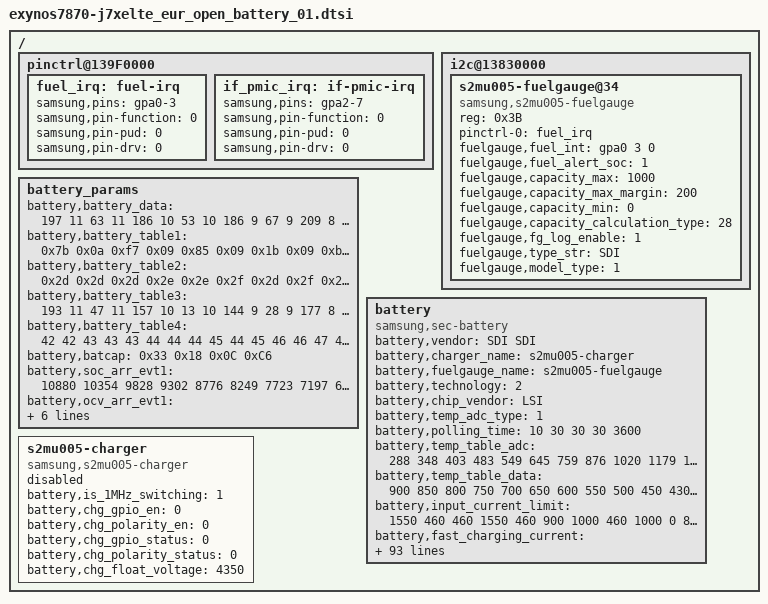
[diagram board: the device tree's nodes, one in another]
/*
 * SAMSUNG UNIVERSAL5433 board device tree source
 *
 * Copyright (c) 2013 Samsung Electronics Co., Ltd.
 *		http://www.samsung.com
 *
 * This program is free software; you can redistribute it and/or modify
 * it under the terms of the GNU General Public License version 2 as
 * published by the Free Software Foundation.
*/

/ {
	pinctrl@139F0000 {
		fuel_irq: fuel-irq {
			samsung,pins = "gpa0-3";
			samsung,pin-function = <0>;
			samsung,pin-pud = <0>;
			samsung,pin-drv = <0>;
		};
	};

	pinctrl@139F0000 {
		if_pmic_irq: if-pmic-irq {
			samsung,pins = "gpa2-7";
			samsung,pin-function = <0>;
			samsung,pin-pud = <0>;
			samsung,pin-drv = <0>;
		};
	};

	i2c@13830000 {
		status = "okay";
		s2mu005-fuelgauge@34 {
			compatible = "samsung,s2mu005-fuelgauge";
			reg = <0x3B>;
			pinctrl-names = "default";
			pinctrl-0 = <&fuel_irq>;
			fuelgauge,fuel_int = <&gpa0 3 0>;
			fuelgauge,fuel_alert_soc = <1>;
			fuelgauge,capacity_max = <1000>;
			fuelgauge,capacity_max_margin = <200>;
			fuelgauge,capacity_min = <0>;
			fuelgauge,capacity_calculation_type = <28>;
			fuelgauge,fg_log_enable = <1>;
			fuelgauge,type_str = "SDI";
			fuelgauge,model_type = <1>;
		};
	};

	battery_params {
			battery,battery_data =
			<
				/***** battery data for 4.35 *****/
				/* battery,battery_table3 */
				197 11 63 11 186 10 53 10 186 9
				67 9 209 8 104 8 4 8 173 7
				75 7 233 6 174 6 130 6 95 6
				66 6 32 6 244 5 188 5 138 5
				241 4 146 1 135 9 18 9 156 8
				38 8 177 7 59 7 197 6 80 6
				218 5 101 5 239 4 121 4 4 4
				142 3 24 3 163 2 45 2 183 1
				66 1 204 0 86 0 225 15

				/* battery,battery_table4 */
				56 56 56 55 55 56 55 55 55 55
				55 55 56 57 57 58 59 61 64 69
				87 158

				/* battery,batcap */
				0x2F 0xA8 0x0B 0xEA /* [0x0F] [0x0E] [0x11] [0x10] */
				/* battery,accum */
				0x00 0x08 /* [0x44] [0x45] */

				/* battery,soc_arr_val */
				11911 11336 10762 10188 9613 9039 8464 7890 7315 6741 6167 5592 5018 4443 3869 3294 2720 2146 1571 997 422 (-152)
				/* battery,ocv_arr_val */
				44710 44058 43406 42756 42157 41575 41022 40507 40020 39595 39117 38638 38351 38136 37965 37820 37654 37444 37170 36926 36175 31965

				/***** battery data for 4.33 *****/
				/* battery,battery_table3 */
				101 11 223 10 90 10 213 9 96 9
				241 8 138 8 24 8 200 7 115 7
				13 7 199 6 150 6 112 6 81 6
				53 6 21 6 237 5 182 5 137 5
				238 4 177 1 216 8 107 8 253 7
				144 7 34 7 180 6 71 6 217 5
				107 5 254 4 144 4 35 4 181 3
				71 3 218 2 108 2 255 1 145 1
				35 1 182 0 72 0 219 15

				/* battery,battery_table4 */
				54 54 55 55 56 56 56 57 57 56
				57 58 60 60 61 61 62 64 68 76
				101 172

				/* battery,batcap */
				0x30 0xD4 0x0C 0x35 /* [0x0F] [0x0E] [0x11] [0x10] */
				/* battery,accum */
				0x00 0x08 /* [0x44] [0x45] */

				/* battery,soc_arr_val */
				11056 10522 9987 9452 8916 8381 7846 7310 6775 6240 5705 5170 4634 4099 3564 3028 2493 1958 1423 887 352 (-183)
				/* battery,ocv_arr_val */
				44243 43591 42939 42290 41717 41177 40674 40117 39729 39311 38814 38471 38235 38049 37897 37760 37603 37409 37140 36918 36160 32115

				/***** battery data for 4.31 *****/
				/* battery,battery_table3 */
				57 11 183 10 54 10 181 9 66 9
				214 8 119 8 252 7 182 7 93 7
				249 6 186 6 141 6 105 6 76 6
				47 6 13 6 228 5 171 5 131 5
				156 4 69 2 217 8 107 8 253 7
				143 7 32 7 178 6 68 6 214 5
				104 5 250 4 139 4 29 4 175 3
				65 3 211 2 101 2 246 1 136 1
				26 1 172 0 62 0 208 15

				/* battery,battery_table4 */
				53 53 53 53 54 54 55 55 56 56
				56 56 57 58 59 60 61 63 65 72
				98 168
				
				/* battery,batcap */
				0x30 0x48 0x0C 0x12 /* [0x0F] [0x0E] [0x11] [0x10] */
				/* battery,accum */
				0x00 0x08 /* [0x44] [0x45] */

				/* battery,soc_arr_val */
				11060 10522 9984 9446 8908 8370 7833 7295 6757 6219 5681 5143 4605 4067 3529 2990 2453 1916 1378 840 302 (-236)
				/* battery,ocv_arr_val */
				44029 43396 42763 42135 41573 41047 40580 39982 39637 39202 38717 38410 38190 38014 37869 37729 37566 37363 37085 36889 35761 32836
				

				/***** battery data for 4.29 *****/
				/* battery,battery_table3 */
				15 11 142 10 14 10 143 9 28 9
				179 8 81 8 225 7 149 7 52 7
				221 6 166 6 125 6 92 6 64 6
				32 6 253 5 204 5 141 5 120 5
				186 3 111 1 220 8 107 8 250 7
				137 7 24 7 167 6 55 6 198 5
				85 5 228 4 115 4 2 4 145 3
				33 3 176 2 63 2 206 1 93 1
				236 0 123 0 10 0 154 15

				/* battery,battery_table4 */
				53 53 53 54 54 54 55 55 55 55
				55 56 57 58 59 59 61 63 67 75
				103 165

				/* battery,batcap */
				0x2F 0x80 0x0B 0xE0 /* [0x0F] [0x0E] [0x11] [0x10] */
				/* battery,accum */
				0x00 0x08 /* [0x44] [0x45] */

				/* battery,soc_arr_val */
				11073 10522 9971 9420 8869 8318 7766 7215 6664 6113 5562 5011 4460 3909 3358 2807 2255 1704 1153 602 51 (-500)
				/* battery,ocv_arr_val */
				43822 43195 42568 41948 41388 40876 40395 39848 39476 39002 38579 38313 38112 37949 37813 37658 37484 37244 36939 36835 34659 31790
				

				/***** battery data for 4.24 *****/
				149 10 36 10 178 9 65 9 219 8
				130 8 15 8 203 7 123 7 26 7
				211 6 163 6 125 6 94 6 68 6
				41 6 8 6 224 5 171 5 132 5
				218 4 72 2 216 8 107 8 253 7
				144 7 34 7 181 6 71 6 217 5
				108 5 254 4 145 4 35 4 182 3
				72 3 219 2 109 2 0 2 146 1
				36 1 183 0 73 0 220 15

				/* battery,battery_table4 */
				51 51 52 53 54 54 54 53 54 54
				54 55 56 57 59 60 61 62 66 72
				95 176

				/* battery,batcap */
				0x2D 0xF0 0x0B 0x7C /* [0x0F] [0x0E] [0x11] [0x10] */
				/* battery,accum */
				0x00 0x08 /* [0x44] [0x45] */

				/* battery,soc_arr_val */
				11056 10522 9987 9452 8917 8382 7846 7312 6777 6242 5707 5172 4638 4103 3568 3033 2498 1963 1428 893 358 (-177)
				/* battery,ocv_arr_val */
				43228 42674 42120 41567 41069 40634 40072 39739 39349 38877 38528 38295 38111 37961 37834 37698 37537 37345 37086 36895 36064 32854
			>;
			battery,battery_table1 = <0x7b 0x0a 0xf7 0x09 0x85 0x09 0x1b 0x09 0xb4 0x08
					0x60 0x08 0xd5 0x07 0xaa 0x07 0x5e 0x07 0xf9 0x06
					0xb7 0x06 0x8b 0x06 0x68 0x06 0x4d 0x06 0x36 0x06
					0x1a 0x06 0xf2 0x05 0xbf 0x05 0x87 0x05 0x68 0x05
					0x66 0x05 0x33 0x02 0xc1 0x07 0x62 0x07 0x03 0x07
					0xa4 0x06 0x46 0x06 0xe7 0x05 0x88 0x05 0x29 0x05
					0xca 0x04 0x6b 0x04 0x0c 0x04 0xad 0x03 0x4f 0x03
					0xf0 0x02 0x91 0x02 0x32 0x02 0xd3 0x01 0x74 0x01
					0x15 0x01 0xb6 0x00 0x57 0x00 0xf9 0x0f>;

			battery,battery_table2 = <0x2d 0x2d 0x2d 0x2e 0x2e 0x2f 0x2d 0x2f 0x2f 0x2e
					0x2f 0x2e 0x2e 0x2f 0x2e 0x2e 0x2f 0x2f 0x2f 0x2e
					0x2f 0x9a>;

			battery,battery_table3 = <193 11 47 11 157 10 13 10 144 9
					28 9 177 8 74 8 208 7 145 7
					53 7 214 6 155 6 114 6 83 6
					60 6 38 6 2 6 201 5 144 5
					84 5 20 2 180 8 72 8 221 7
					113 7 5 7 153 6 46 6 194 5
					86 5 234 4 127 4 19 4 167 3
					59 3 208 2 100 2 248 1 140 1
					33 1 181 0 73 0 221 15>;
			battery,battery_table4 = <42 42 43 43 43 44 44 44 45 44
					45 46 46 47 48 49 50 51 53 58
					73 154>;

			battery,batcap = <0x33 0x18 0x0C 0xC6>; /* [0x0F] [0x0E] [0x11] [0x10] */

			battery,soc_arr_evt1 = <10880 10354 9828 9302 8776 8249 7723 7197 6671 6145 5619 5093 4566 4040 3514 2988 2462 1936 1409 883 357 (-168)>;
			battery,ocv_arr_evt1 = <44691 43979 43267 42562 41954 41386 40862 40361 39764 39460 39008 38545 38258 38059 37905 37794 37687 37510 37234 36953 36661 32596>;

			battery,soc_arr_evt2 = <10880 10354 9828 9302 8776 8249 7723 7197 6671 6145 5619 5093 4566 4040 3514 2988 2462 1936 1409 883 357 (-168)>;
			battery,ocv_arr_evt2 = <44691 43979 43267 42562 41954 41386 40862 40361 39764 39460 39008 38545 38258 38059 37905 37794 37687 37510 37234 36953 36661 32596>;
			battery,data_ver = <0x04>;
	};

	battery {
		status = "okay";

		pinctrl-names = "default";

		compatible = "samsung,sec-battery";
		battery,vendor = "SDI SDI";
		battery,charger_name = "s2mu005-charger";
		battery,fuelgauge_name = "s2mu005-fuelgauge";
		battery,technology = <2>; /* POWER_SUPPLY_TECHNOLOGY_LION */

		battery,chip_vendor = "LSI";
		battery,temp_adc_type = <1>; /* SEC_BATTERY_ADC_TYPE_AP */

		battery,polling_time = <10 30 30 30 3600>;

		battery,temp_table_adc = <288 348 403 483 549 645 759 876 1020 1179 1249 1367 1572 1790 2023
								2236 2465 2678 2883 3072 3184 3251 3387 3503 3600 >;

		battery,temp_table_data = <900 850 800 750 700 650 600 550 500 450 430 400 350 300 250
								200 150 100 50 0 (-30) (-50) (-100) (-150) (-200)>;

		battery,input_current_limit = <1550 460 460 1550 460 900 1000 460 1000 0 820 820 820 1900 1550 0 0 400 700 1300 300 1000 1550 0 1667 1667 1000 1667 80 1800 1667 1400 1000 1000 820 820>;
		battery,fast_charging_current = <1700 0 0 1700 460 1200 1000 460 1200 0 1200 1200 1200 1700 2100 0 0 400 700 1300 300 1000 1500 0 2550 2550 1000 2550 80 1800 1000 1400 0 1000 1200 1200>;
		battery,full_check_current_1st = <350 0 0 350 350 350 350 350 350 0 350 350 350 350 350 0 0 350 350 350 350 350 350 0 350 350 350 350 0 350 350 350 0 350 350 350>;
		battery,full_check_current_2nd = <175 0 0 175 175 175 175 175 175 0 175 175 175 175 175 0 0 175 175 175 175 175 175 0 175 175 175 175 0 175 175 175 0 175 175 175>;

		battery,wireless_cc_cv = <86>;
		battery,inbat_voltage = <1>;

		battery,inbat_voltage_table_adc = <3120 3101 3061 3038 3001 2956 2920 2887 2856 2814
						2793 2754 2720 2677 2641 2613 2572 2531 2502 2467 2436>;
		battery,inbat_voltage_table_data = <438 435 430 425 420 415 410 405 400 395
						390 385 380 375 370 365 360 355 350 345 340>;

		battery,adc_check_count = <5>;

		battery,cable_check_type = <4>; /* SEC_BATTERY_CABLE_CHECK_PSY */
		battery,cable_source_type = <1>; /* SEC_BATTERY_CABLE_SOURCE_EXTERNAL */
		battery,polling_type = <1>; /* SEC_BATTERY_MONITOR_ALARM */
		battery,monitor_initial_count = <0>;

		battery,battery_check_type = <5>; /* SEC_BATTERY_CHECK_CHARGER */
		battery,check_count = <0>;

		battery,ovp_uvlo_check_type = <3>; /* SEC_BATTERY_OVP_UVLO_CHGPOLLING */

		battery,check_adc_max = <1440>;
		battery,check_adc_min = <0>;

		battery,thermal_source = <2>; /* SEC_BATTERY_THERMAL_SOURCE_ADC */

		battery,temp_check_type = <2>; /* SEC_BATTERY_TEMP_CHECK_TEMP */
		battery,temp_check_count = <1>;
		battery,temp_highlimit_threshold_normal = <800>;
		battery,temp_highlimit_recovery_normal = <750>;
		battery,temp_high_threshold_normal = <500>;
		battery,temp_high_recovery_normal = <450>;
		battery,temp_low_threshold_normal = <0>;
		battery,temp_low_recovery_normal = <50>;
		battery,temp_highlimit_threshold_lpm = <800>;
		battery,temp_highlimit_recovery_lpm = <750>;
		battery,temp_high_threshold_lpm = <500>;
		battery,temp_high_recovery_lpm = <450>;
		battery,temp_low_threshold_lpm = <0>;
		battery,temp_low_recovery_lpm = <50>;

		battery,full_check_type = <2>; /* SEC_BATTERY_FULLCHARGED_FG_CURRENT */
		battery,full_check_type_2nd = <2>; /* SEC_BATTERY_FULLCHARGED_FG_CURRENT */
		battery,full_check_count = <1>;
		battery,chg_gpio_full_check = <0>;
		battery,chg_polarity_full_check = <1>;

		battery,chg_high_temp_1st = <530>;
		battery,chg_high_temp_2nd = <530>;
		battery,chg_high_temp_recovery = <525>;
		battery,chg_charging_limit_current = <1300>;
		battery,chg_charging_limit_current_2nd = <1300>;
		battery,chg_skip_check_capacity = <10>;
		battery,chg_skip_check_time = <600>;

		battery,wpc_high_temp = <420>;
		battery,wpc_high_temp_recovery = <410>;
		battery,wpc_charging_limit_current = <450>;

		/* SEC_BATTERY_FULL_CONDITION_SOC |
		   SEC_BATTERY_FULL_CONDITION_NOTIMEFULL |
		   SEC_BATTERY_FULL_CONDITION_VCELL */
		battery,full_condition_type = <15>;
		battery,full_condition_soc = <93>;
		battery,full_condition_vcell = <4290>;

		battery,recharge_check_count = <2>;
		battery,recharge_condition_type = <4>; /* SEC_BATTERY_RECHARGE_CONDITION_VCELL */
		battery,recharge_condition_soc = <98>;
		battery,recharge_condition_vcell = <4250>;

		battery,charging_total_time = <21600>;
		battery,recharging_total_time = <5400>;
		battery,charging_reset_time = <0>;
		
		battery,expired_time = <15000>;
		battery,recharging_expired_time = <5400>;
		battery,standard_curr = <1700>;

		battery,chg_float_voltage = <4350>;

		battery,self_discharging_en;
		battery,force_discharging_limit = <650>;
		battery,force_discharging_recov = <550>;
		battery,self_discharging_voltage_limit = <4250>;
		battery,discharging_adc_max = <2600>;
		battery,discharging_adc_min = <1700>;
		battery,discharging_ntc_limit = <2750>;

		battery,swelling_high_temp_block = <410>;
		battery,swelling_high_temp_recov = <390>;

		battery,swelling_low_temp_2step_mode = <1>;
		battery,swelling_low_temp_block_1st = <150>;
		battery,swelling_low_temp_recov_1st = <200>;
		battery,swelling_low_temp_block_2nd = <100>;
		battery,swelling_low_temp_recov_2nd = <150>;
		
		battery,swelling_low_temp_current = <500>;	/* 0.3C */
		battery,swelling_low_temp_topoff = <175>;	/* 0.05C */
		battery,swelling_high_temp_current = <1100>;	/* 0.45C */
		battery,swelling_high_temp_topoff = <175>;	/* 0.05C */
		
		battery,swelling_drop_float_voltage = <4150>;
		battery,swelling_high_rechg_voltage = <4000>;
		battery,swelling_low_rechg_voltage = <4000>;

		battery,siop_input_limit_current = <1550>;
		battery,siop_charging_limit_current = <1000>;

		/* cycle(week), chg_float_voltage, recharge_condition_vcell, full_condition_vcell, full_condition_soc */
		battery,age_data = <0 4350 4250 4250 93
			28 4330 4230 4230 91
			36 4310 4210 4210 89>;

		io-channels = <&exynos_adc 1>, <&exynos_adc 3>, <&exynos_adc 6>, <&exynos_adc 5>, <&exynos_adc 7>;
		io-channel-names = "adc-temp", "adc-chg-temp", "adc-in-bat", "adc-dischg", "adc-dischg-ntc";
		#io-channel-cells = <5>;
		io-channel-ranges;
	};

	s2mu005-charger {
		status = "disable";
		compatible = "samsung,s2mu005-charger";
		battery,is_1MHz_switching = <1>;
		battery,chg_gpio_en = <0>;
		battery,chg_polarity_en = <0>;
		battery,chg_gpio_status = <0>;
		battery,chg_polarity_status = <0>;
		battery,chg_float_voltage = <4350>;
	};
};
